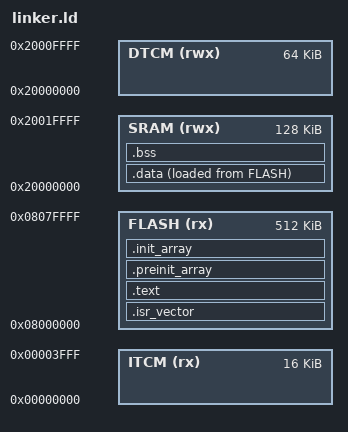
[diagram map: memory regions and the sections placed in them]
/* STM32F7 Linker Script - Cortex-M7 */

ENTRY(_start)

MEMORY
{
    FLASH (rx)  : ORIGIN = 0x08000000, LENGTH = 512K
    SRAM (rwx)  : ORIGIN = 0x20000000, LENGTH = 128K
    DTCM (rwx)  : ORIGIN = 0x20000000, LENGTH = 64K   /* DTCM for Cortex-M7 */
    ITCM (rx)   : ORIGIN = 0x00000000, LENGTH = 16K   /* ITCM for fast code */
}

_stack_size = 8K;
_heap_size = 32K;

SECTIONS
{
    .isr_vector :
    {
        . = ALIGN(4);
        KEEP(*(.isr_vector))
        . = ALIGN(4);
    } > FLASH

    .text :
    {
        . = ALIGN(4);
        *(.text)
        *(.text*)
        *(.rodata)
        *(.rodata*)
        . = ALIGN(4);
        _etext = .;
    } > FLASH

    .preinit_array :
    {
        . = ALIGN(4);
        __preinit_array_start = .;
        KEEP(*(.preinit_array*))
        __preinit_array_end = .;
    } > FLASH

    .init_array :
    {
        . = ALIGN(4);
        __init_array_start = .;
        KEEP(*(.init_array*))
        __init_array_end = .;
    } > FLASH

    _sidata = LOADADDR(.data);
    .data :
    {
        . = ALIGN(4);
        _sdata = .;
        *(.data)
        *(.data*)
        . = ALIGN(4);
        _edata = .;
    } > SRAM AT > FLASH

    .bss :
    {
        . = ALIGN(4);
        _sbss = .;
        *(.bss)
        *(.bss*)
        *(COMMON)
        . = ALIGN(4);
        _ebss = .;
    } > SRAM

    _estack = ORIGIN(SRAM) + LENGTH(SRAM);
}
